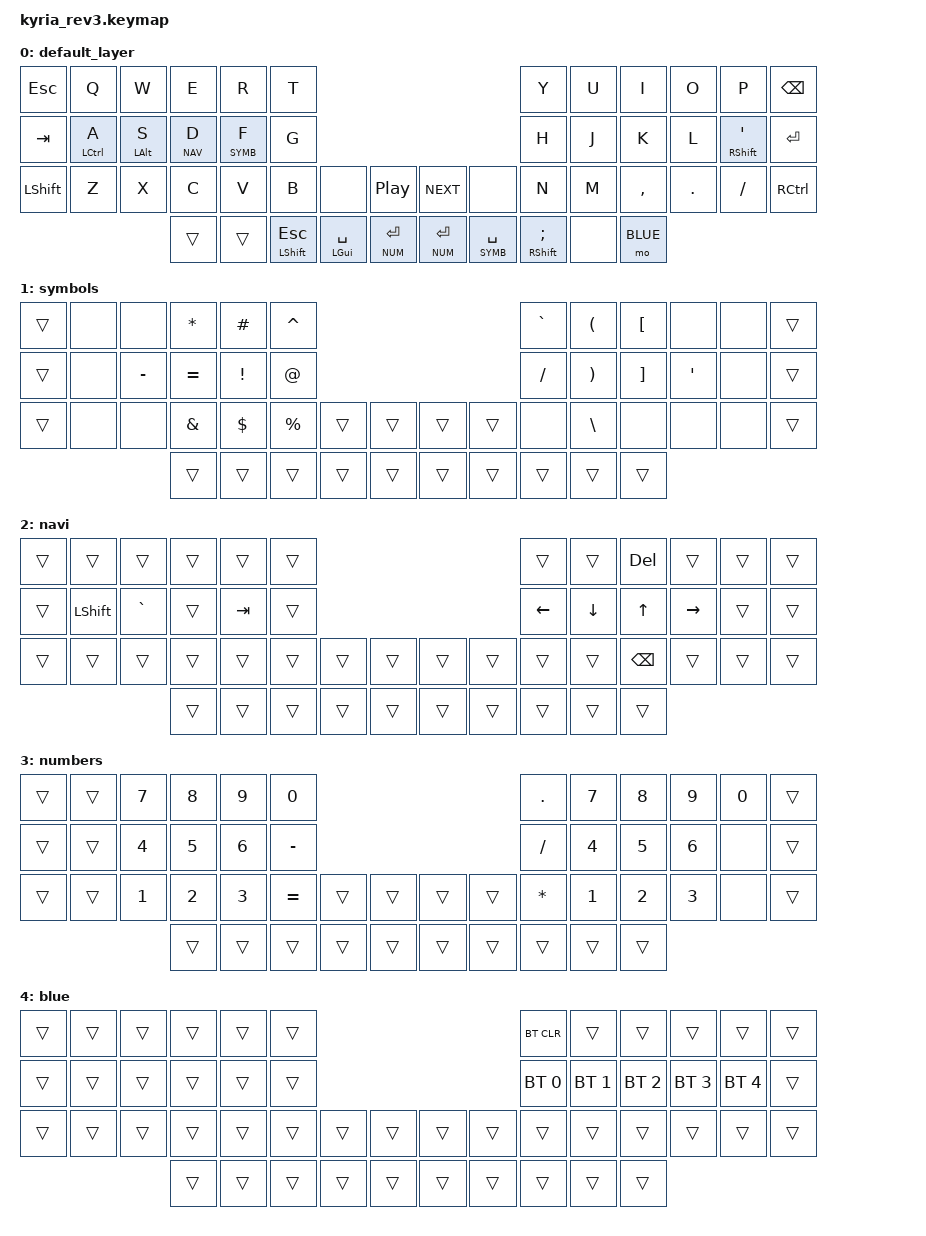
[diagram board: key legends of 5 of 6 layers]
/*
 * Copyright (c) 2023 The ZMK Contributors
 *
 * SPDX-License-Identifier: MIT
 */

#include <behaviors.dtsi>
#include <dt-bindings/zmk/bt.h>
#include <dt-bindings/zmk/keys.h>
#include <dt-bindings/zmk/outputs.h>

// Prefer output over bluetooth when connected via USB
// &out OUT_BLE

// None/Trans
#define _____ &none
#define t____ &trans

#define DEFAULT 0
#define SYMB    1
#define NAV     2
#define NUM     3
#define BLUE    4

// Encoders
&sensors        { triggers-per-rotation = <30>; };
&left_encoder   { steps = <60>; };
&right_encoder  { steps = <60>; };

/* Uncomment this block if using RGB
&led_strip {
    chain-length = <6>;
    // chain-length = <31>; // Uncomment if using both per-key and underglow LEDs
    // chain-length = <25>; // Uncomment if using only per-key LEDs.
};
 */
/ {
    behaviors {
        hm: homerow_mods {
            compatible = "zmk,behavior-hold-tap";
            label = "HOMEROW_MODS";
            #binding-cells = <2>;
            tapping-term-ms = <150>;
            quick_tap_ms = <0>;
            flavor = "tap-preferred";
            bindings = <&kp>, <&kp>;
        };
    };
    keymap {
        compatible = "zmk,keymap";

        default_layer {
bindings = <
&kp ESC    &kp Q        &kp W       &kp E      &kp R       &kp T                                                                          &kp Y           &kp U  &kp I      &kp O    &kp P          &kp BSPC
&kp TAB    &hm LCTRL A  &hm LALT S  &lt NAV D  &lt SYMB F  &kp G                                                                          &kp H           &kp J  &kp K      &kp L    &hm RSHFT SQT  &kp ENTER
&kp LSHFT  &kp Z        &kp X       &kp C      &kp V       &kp B          _____         &kp C_PP              &kp C_NEXT     _____        &kp N           &kp M  &kp COMMA  &kp DOT  &kp FSLH       &kp RCTRL
                                    t____      t____       &hm LSHFT ESC  &hm LGUI SPC  &lt NUM ENTER         &lt NUM ENTER  &lt SYMB SPC &hm RSHFT SEMI  _____  &mo BLUE   
>;

sensor-bindings = <&inc_dec_kp C_VOL_UP C_VOL_DN &inc_dec_kp PG_UP PG_DN>;
        };

        symbols {
            bindings = <
t____  _____  _____     &kp STAR   &kp HASH   &kp CARET                                  &kp GRAVE  &kp LPAR  &kp LBKT  _____     _____  t____ 
t____  _____  &kp MINUS &kp EQUAL  &kp EXCL   &kp AT                                     &kp FSLH   &kp RPAR  &kp RBKT  &kp SQT   _____  t____
t____  _____  _____     &kp AMPS   &kp DLLR   &kp PRCNT  t____  t____      t____  t____  _____      &kp BSLH  _____     _____     _____  t____
                        t____      t____      t____      t____  t____      t____  t____  t____      t____     t____
            >;
sensor-bindings = <&inc_dec_kp t____ t____ &inc_dec_kp t____ t____>;
        };

        navi {
            bindings = <
t____  t____      t____      t____  t____    t____                                  t____     t____     &kp DEL   t____      t____  t____ 
t____  &kp LSHFT  &kp GRAVE  t____  &kp TAB  t____                                  &kp LEFT  &kp DOWN  &kp UP    &kp RIGHT  t____  t____ 
t____  t____      t____      t____  t____    t____  t____  t____      t____  t____  t____     t____     &kp BSPC  t____      t____  t____ 
                             t____  t____    t____  t____  t____      t____  t____  t____     t____     t____
            >;
sensor-bindings = <&inc_dec_kp t____ t____ &inc_dec_kp t____ t____>;
        };

        numbers {
            bindings = <
t____  t____  &kp N7  &kp N8  &kp N9  &kp N0                                     &kp DOT   &kp N7  &kp N8  &kp N9  &kp N0    t____ 
t____  t____  &kp N4  &kp N5  &kp N6  &kp MINUS                                  &kp FSLH  &kp N4  &kp N5  &kp N6  _____     t____ 
t____  t____  &kp N1  &kp N2  &kp N3  &kp EQUAL  t____  t____      t____  t____  &kp STAR  &kp N1  &kp N2  &kp N3  _____     t____ 
                      t____   t____   t____      t____  t____      t____  t____  t____     t____   t____
            >;
sensor-bindings = <&inc_dec_kp t____ t____ &inc_dec_kp t____ t____>;
        };

        blue {
// I added a zero key because Zephyr won't compile with a only-transparent layer
            bindings = <
t____  t____  t____  t____  t____  t____                                  &bt BT_CLR    t____         t____         t____         t____         t____
t____  t____  t____  t____  t____  t____                                  &bt BT_SEL 0  &bt BT_SEL 1  &bt BT_SEL 2  &bt BT_SEL 3  &bt BT_SEL 4  t____
t____  t____  t____  t____  t____  t____  t____  t____      t____  t____  t____         t____         t____         t____         t____         t____
                     t____  t____  t____  t____  t____      t____  t____  t____         t____         t____
            >;
sensor-bindings = <&inc_dec_kp t____ t____ &inc_dec_kp t____ t____>;
        };

        // This layer is for easier copy/paste when creating new keymaps, so you have transparent keys already added
        trans {
// -------------------------------------------------------------------------------------------------------------------------
// |         |         |         |         |         |                   |         |         |         |         |         |
// |         |         |         |         |         |                   |         |         |         |         |         |
// |         |         |         |         |         |                   |         |         |         |         |         |
//           |         |         |                                                           |         |         |
//                               |         |         |                   |         |         |
//                                         |         |         |         |         |
//                                         |         |         |         |         |
// I added a zero key because Zephyr won't compile with a only-transparent layer
            bindings = <
t____  &kp KP_N0 t____  t____  t____  t____                                  t____  t____  t____  t____  t____  t____ 
t____  t____     t____  t____  t____  t____                                  t____  t____  t____  t____  t____  t____ 
t____  t____     t____  t____  t____  t____                                  t____  t____  t____  t____  t____  t____ 
                        t____  t____  t____  t____  t____      t____  t____  t____  t____  t____
            >;
        };
    };
};
